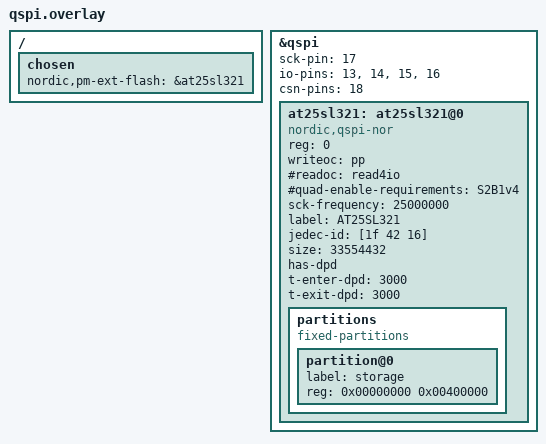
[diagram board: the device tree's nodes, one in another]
/*
 * Copyright (c) 2022 Griffin Adams
 *
 * SPDX-License-Identifier: Apache-2.0
 */

/ {
	chosen {
		nordic,pm-ext-flash = &at25sl321;
	};
};

&qspi {
	status = "okay";
	sck-pin = <17>;
	io-pins = <13>, <14>, <15>, <16>;
	csn-pins = <18>;
	at25sl321: at25sl321@0 {
		compatible = "nordic,qspi-nor";
		reg = <0>;
		/* AT25SL321 has dif opcode for quad, so we're stuck with pp */
		writeoc = "pp";
		/* AT25SL321 supports all readoc options */
		#readoc = "read4io";
		#quad-enable-requirements = "S2B1v4";
		sck-frequency = <25000000>;
		label = "AT25SL321";
		jedec-id = [1f 42 16];
		size = <33554432>;
		has-dpd;
		t-enter-dpd = <3000>;
		t-exit-dpd = <3000>;
	};
};

/delete-node/ &mx25u32;

&at25sl321 {
	partitions {
		compatible = "fixed-partitions";
		#address-cells = <1>;
		#size-cells = <1>;

		partition@0 {
			label = "storage";
			reg = <0x00000000 0x00400000>;
		};
	};
};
